# LPC5410x register map
File version: 0.4
CPU: CM4 r0p0, little endian, no MPU, no FPU, 0x3 interrupt priority bits, 0x0 interrupts
Registers are 32-bit, read-write, reset 0x0 unless marked. A register's access mark holds for its fields unless they carry their own. Offsets are from the block's base; [hi:lo] are bit positions; {n}, {i} and the like mark numbered series.

## SPI0
Base 0x400A4000
Same registers: SPI1 0x400A8000
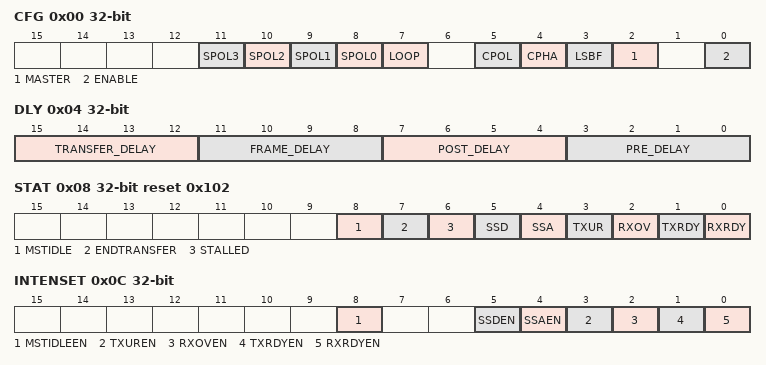
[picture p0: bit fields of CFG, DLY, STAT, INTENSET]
0x00 CFG — SPI Configuration register
  [n+8] SPOL{n} (n=0..3) — SSEL{n} Polarity select.
    0=LOW (Low. The SSEL{n} pin is active low. The value in the SSEL{n} fields of the RXDAT, TXDATCTL, and TXCTL registers related to SSEL{n} is not inverted relative to the pins.); 1=HIGH (High. The SSEL{n} pin is active high. The value in the SSEL{n} fields of the RXDAT, TXDATCTL, and TXCTL registers related to SSEL{n} is inverted relative to the pins.)
  [7] LOOP — Loopback mode enable. Loopback mode applies only to Master mode, and connects transmit and receive data connected together to allow simple software testing.
    0=DISABLED; 1=ENABLED
  [5] CPOL — Clock Polarity select.
    0=LOW (Low. The rest state of the clock (between transfers) is low.); 1=HIGH (High. The rest state of the clock (between transfers) is high.)
  [4] CPHA — Clock Phase select.
    0=CHANGE (Change. The SPI captures serial data on the first clock transition of the transfer (when the clock changes away from the rest state). Data is changed on the following edge.); 1=CAPTURE (Capture. The SPI changes serial data on the first clock transition of the transfer (when the clock changes away from the rest state). Data is captured on the following edge.)
  [3] LSBF — LSB First mode enable.
    0=STANDARD (Standard. Data is transmitted and received in standard MSB first order.); 1=REVERSE (Reverse. Data is transmitted and received in reverse order (LSB first).)
  [2] MASTER — Master mode select.
    0=SLAVE_MODE (Slave mode. The SPI will operate in slave mode. SCK, MOSI, and the SSEL signals are inputs, MISO is an output.); 1=MASTER_MODE (Master mode. The SPI will operate in master mode. SCK, MOSI, and the SSEL signals are outputs, MISO is an input.)
  [0] ENABLE — SPI enable.
    0=DISABLED (Disabled. The SPI is disabled and the internal state machine and counters are reset.); 1=ENABLED (Enabled. The SPI is enabled for operation.)
0x04 DLY — SPI Delay register
  [15:12] TRANSFER_DELAY — Controls the minimum amount of time that the SSEL is deasserted between transfers. 0x0 = The minimum time that SSEL is deasserted is 1 SPI clock time. (Zero added time.) 0x1 = The minimum time that SSEL is deasserted is 2 SPI clock times. 0x2 = The minimum time that SSEL is deasserted is 3 SPI clock times. ... 0xF = The minimum time that SSEL is deasserted is 16 SPI clock times.
  [11:8] FRAME_DELAY — If the EOF flag is set, controls the minimum amount of time between the current frame and the next frame (or SSEL deassertion if EOT). 0x0 = No additional time is inserted. 0x1 = 1 SPI clock time is inserted. 0x2 = 2 SPI clock times are inserted. ... 0xF = 15 SPI clock times are inserted.
  [7:4] POST_DELAY — Controls the amount of time between the end of a data transfer and SSEL deassertion. 0x0 = No additional time is inserted. 0x1 = 1 SPI clock time is inserted. 0x2 = 2 SPI clock times are inserted. ... 0xF = 15 SPI clock times are inserted.
  [3:0] PRE_DELAY — Controls the amount of time between SSEL assertion and the beginning of a data transfer. There is always one SPI clock time between SSEL assertion and the first clock edge. This is not considered part of the pre-delay. 0x0 = No additional time is inserted. 0x1 = 1 SPI clock time is inserted. 0x2 = 2 SPI clock times are inserted. ... 0xF = 15 SPI clock times are inserted.
0x08 STAT reset 0x102 — SPI Status. Some status flags can be cleared by writing a 1 to that bit position
  [8] MSTIDLE — Master idle status flag. This bit is 1 whenever the SPI master function is fully idle. This means that the transmit holding register is empty and the transmitter is not in the process of sending data.
  [7] ENDTRANSFER — End Transfer control bit. Software can set this bit to force an end to the current transfer when the transmitter finishes any activity already in progress, as if the EOT flag had been set prior to the last transmission. This capability is included to support cases where it is not known when transmit data is written that it will be the end of a transfer. The bit is cleared when the transmitter becomes idle as the transfer comes to an end. Forcing an end of transfer in this manner causes any specified FRAME_DELAY and TRANSFER_DELAY to be inserted.
  [6] STALLED — Stalled status flag. This indicates whether the SPI is currently in a stall condition.
  [5] SSD — Slave Select Deassert. This flag is set whenever any asserted slave selects transition to deasserted, in both master and slave modes. This allows determining when the SPI transmit/receive functions become idle. This flag is cleared by software.
  [4] SSA — Slave Select Assert. This flag is set whenever any slave select transitions from deasserted to asserted, in both master and slave modes. This allows determining when the SPI transmit/receive functions become busy, and allows waking up the device from reduced power modes when a slave mode access begins. This flag is cleared by software.
  [3] TXUR — Transmitter Underrun interrupt flag. This flag applies only to slave mode (Master = 0). In this case, the transmitter must begin sending new data on the next input clock if the transmitter is idle. If that data is not available in the transmitter holding register at that point, there is no data to transmit and the TXUR flag is set. Data transmitted by the SPI should be considered undefined if TXUR is set.
  [2] RXOV — Receiver Overrun interrupt flag. This flag applies only to slave mode (Master = 0). This flag is set when the beginning of a received character is detected while the receiver buffer is still in use. If this occurs, the receiver buffer contents are preserved, and the incoming data is lost. Data received by the SPI should be considered undefined if RxOv is set.
  [1] TXRDY — Transmitter Ready flag. When 1, this bit indicates that data may be written to the transmit buffer. Previous data may still be in the process of being transmitted. Cleared when data is written to TXDAT or TXDATCTL until the data is moved to the transmit shift register.
  [0] RXRDY — Receiver Ready flag. When 1, indicates that data is available to be read from the receiver buffer. Cleared after a read of the RXDAT register.
0x0C INTENSET — SPI Interrupt Enable read and Set. A complete value may be read from this register. Writing a 1 to any implemented bit position causes that bit to be set.
  [8] MSTIDLEEN — Master idle interrupt enable
    0=DISABLED (Disabled. No interrupt will be generated when the SPI master function is idle.); 1=ENABLED (Enabled. An interrupt will be generated when the SPI master function is idle.)
  [5] SSDEN — Slave select deassert interrupt enable. Determines whether an interrupt occurs when the Slave Select is deasserted.
    0=DISABLED (Disabled. No interrupt will be generated when all asserted Slave Selects transition to deasserted.); 1=ENABLED (Enabled. An interrupt will be generated when all asserted Slave Selects transition to deasserted.)
  [4] SSAEN — Slave select assert interrupt enable. Determines whether an interrupt occurs when the Slave Select is asserted.
    0=DISABLED (Disabled. No interrupt will be generated when any Slave Select transitions from deasserted to asserted.); 1=ENABLED (Enabled. An interrupt will be generated when any Slave Select transitions from deasserted to asserted.)
  [3] TXUREN — TX underrun interrupt enable. Determines whether an interrupt occurs when a transmitter underrun occurs. This happens in slave mode when there is a need to transmit data when none is available.
    0=DISABLED (Disabled. No interrupt will be generated when the transmitter underruns.); 1=ENABLED (Enabled. An interrupt will be generated if the transmitter underruns.)
  [2] RXOVEN — RX overrun interrupt enable. Determines whether an interrupt occurs when a receiver overrun occurs. This happens in slave mode when there is a need for the receiver to move newly received data to the RXDAT register when it is already in use. The interface prevents receiver overrun in Master mode by not allowing a new transmission to begin when a receiver overrun would otherwise occur.
    0=DISABLED (Disabled. No interrupt will be generated when a receiver overrun occurs.); 1=ENABLED (Enabled. An interrupt will be generated if a receiver overrun occurs.)
  [1] TXRDYEN — TX ready interrupt enable. Determines whether an interrupt occurs when the transmitter holding register is available.
    0=DISABLED (Disabled. No interrupt will be generated when the transmitter holding register is available.); 1=ENABLED (Enabled. An interrupt will be generated when data may be written to TXDAT.)
  [0] RXRDYEN — RX ready interrupt enable. Determines whether an interrupt occurs when receiver data is available.
    0=DISABLED (Disabled. No interrupt will be generated when receiver data is available.); 1=ENABLED (Enabled. An interrupt will be generated when receiver data is available in the RXDAT register.)
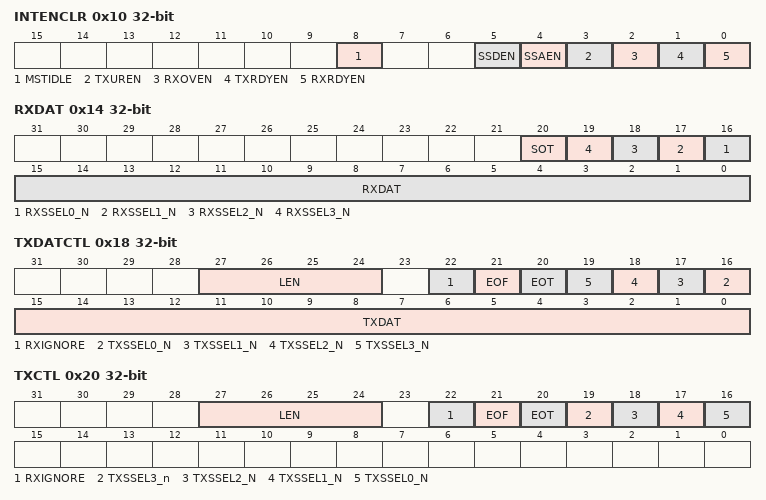
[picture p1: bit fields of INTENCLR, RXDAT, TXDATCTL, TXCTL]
0x10 INTENCLR wo reset not defined — SPI Interrupt Enable Clear. Writing a 1 to any implemented bit position causes the corresponding bit in INTENSET to be cleared.
  [8] MSTIDLE — Writing 1 clears the corresponding bits in the MSTIDLE register.
  [5] SSDEN — Writing 1 clears the corresponding bits in the INTENSET register.
  [4] SSAEN — Writing 1 clears the corresponding bits in the INTENSET register.
  [3] TXUREN — Writing 1 clears the corresponding bits in the INTENSET register.
  [2] RXOVEN — Writing 1 clears the corresponding bits in the INTENSET register.
  [1] TXRDYEN — Writing 1 clears the corresponding bits in the INTENSET register.
  [0] RXRDYEN — Writing 1 clears the corresponding bits in the INTENSET register.
0x14 RXDAT ro reset not defined read-modifies — SPI Receive Data
  [20] SOT — Start of Transfer flag. This flag will be 1 if this is the first data after the SSELs went from deasserted to asserted (i.e., any previous transfer has ended). This information can be used to identify the first piece of data in cases where the transfer length is greater than 16 bit.
  [n+16] RXSSEL{n}_N (n=0..3) — Slave Select for receive. This field allows the state of the SSEL{n} pin to be saved along with received data. The value will reflect the SSEL{n} pin for both master and slave operation. A zero indicates that a slave select is active. The actual polarity of each slave select pin is configured by the related SPOL bit in CFG.
  [15:0] RXDAT — Receiver Data. This contains the next piece of received data. The number of bits that are used depends on the LEN setting in TXCTL / TXDATCTL.
0x18 TXDATCTL — SPI Transmit Data with Control
  [27:24] LEN — Data Length. Specifies the data length from 1 to 16 bits. Note that transfer lengths greater than 16 bits are supported by implementing multiple sequential transmits. 0x0 = Data transfer is 1 bit in length. 0x1 = Data transfer is 2 bits in length. 0x2 = Data transfer is 3 bits in length. ... 0xF = Data transfer is 16 bits in length.
  [22] RXIGNORE — Receive Ignore. This allows data to be transmitted using the SPI without the need to read unneeded data from the receiver.Setting this bit simplifies the transmit process and can be used with the DMA.
    0=READ_RECEIVED_DATA (Read received data. Received data must be read in order to allow transmission to progress. In slave mode, an overrun error will occur if received data is not read before new data is received.); 1=IGNORE_RECEIVED_DATA (Ignore received data. Received data is ignored, allowing transmission without reading unneeded received data. No receiver flags are generated.)
  [21] EOF — End of Frame. Between frames, a delay may be inserted, as defined by the FRAME_DELAY value in the DLY register. The end of a frame may not be particularly meaningful if the FRAME_DELAY value = 0. This control can be used as part of the support for frame lengths greater than 16 bits.
    0=DATA_NOT_EOF (Data not EOF. This piece of data transmitted is not treated as the end of a frame.); 1=DATA_EOF (Data EOF. This piece of data is treated as the end of a frame, causing the FRAME_DELAY time to be inserted before subsequent data is transmitted.)
  [20] EOT — End of Transfer. The asserted SSEL will be deasserted at the end of a transfer, and remain so for at least the time specified by the Transfer_delay value in the DLY register.
    0=SSEL_NOT_DEASSERTED (SSEL not deasserted. This piece of data is not treated as the end of a transfer. SSEL will not be deasserted at the end of this data.); 1=SSEL_DEASSERTED (SSEL deasserted. This piece of data is treated as the end of a transfer. SSEL will be deasserted at the end of this piece of data.)
  [n+16] TXSSEL{n}_N (n=0..3) — Transmit Slave Select. This field asserts SSEL{n} in master mode. The output on the pin is active LOW by default. The active state of the SSEL{n} pin is configured by bits in the CFG register.
    0=SSEL{n}_ASSERTED; 1=SSEL{n}_NOT_ASSERTED
  [15:0] TXDAT — Transmit Data. This field provides from 1 to 16 bits of data to be transmitted.
0x1C TXDAT — SPI Transmit Data
  [15:0] DATA — Transmit Data. This field provides from 4 to 16 bits of data to be transmitted.
0x20 TXCTL — SPI Transmit Control
  [27:24] LEN — Data transfer Length.
  [22] RXIGNORE — Receive Ignore.
  [21] EOF — End of Frame.
  [20] EOT — End of Transfer.
  [19] TXSSEL3_n — Transmit Slave Select 3.
  [18] TXSSEL2_N — Transmit Slave Select 2.
  [17] TXSSEL1_N — Transmit Slave Select 1.
  [16] TXSSEL0_N — Transmit Slave Select 0.
0x24 DIV — SPI clock Divider
  [15:0] DIVVAL — Rate divider value. Specifies how the PCLK for the SPI is divided to produce the SPI clock rate in master mode. DIVVAL is -1 encoded such that the value 0 results in PCLK/1, the value 1 results in PCLK/2, up to the maximum possible divide value of 0xFFFF, which results in PCLK/65536.
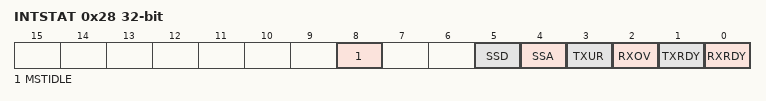
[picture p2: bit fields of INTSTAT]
0x28 INTSTAT ro — SPI Interrupt Status
  [8] MSTIDLE — Master Idle status flag.
  [5] SSD — Slave Select Deassert.
  [4] SSA — Slave Select Assert.
  [3] TXUR — Transmitter Underrun interrupt flag.
  [2] RXOV — Receiver Overrun interrupt flag.
  [1] TXRDY — Transmitter Ready flag.
  [0] RXRDY — Receiver Ready flag.
